# HC32F4A0PGTB register map
File version: 1.0
CPU: CM4 r0p1, little endian, MPU, FPU, 4 interrupt priority bits
Registers are 32-bit, read-write, reset 0x0 unless marked. A register's access mark holds for its fields unless they carry their own. Offsets are from the block's base; [hi:lo] are bit positions; {n}, {i} and the like mark numbered series.

## CAN1 — desc CAN
Base 0x40009000
Same registers: CAN2 0x40078000
0x00 RBUF ro
0x50 TBUF
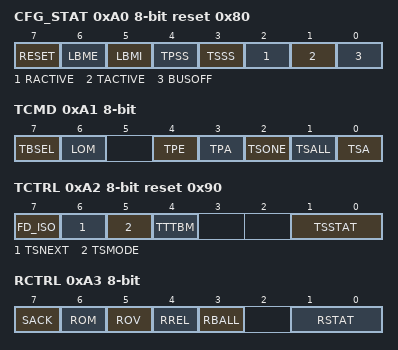
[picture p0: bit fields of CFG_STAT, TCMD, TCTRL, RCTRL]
0xA0 CFG_STAT 8-bit reset 0x80
  [7] RESET, [6] LBME, [5] LBMI, [4] TPSS, [3] TSSS, [2] RACTIVE ro, [1] TACTIVE ro, [0] BUSOFF
0xA1 TCMD 8-bit
  [7] TBSEL, [6] LOM, [4] TPE, [3] TPA, [2] TSONE, [1] TSALL, [0] TSA
0xA2 TCTRL 8-bit reset 0x90
  [7] FD_ISO, [6] TSNEXT, [5] TSMODE, [4] TTTBM, [1:0] TSSTAT ro
0xA3 RCTRL 8-bit
  [7] SACK, [6] ROM, [5] ROV ro, [4] RREL, [3] RBALL, [1:0] RSTAT ro
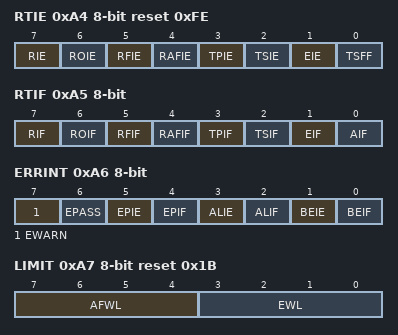
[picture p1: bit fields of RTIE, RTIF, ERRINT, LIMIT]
0xA4 RTIE 8-bit reset 0xFE
  [7] RIE, [6] ROIE, [5] RFIE, [4] RAFIE, [3] TPIE, [2] TSIE, [1] EIE, [0] TSFF ro
0xA5 RTIF 8-bit
  [7] RIF, [6] ROIF, [5] RFIF, [4] RAFIF, [3] TPIF, [2] TSIF, [1] EIF, [0] AIF
0xA6 ERRINT 8-bit
  [7] EWARN ro, [6] EPASS ro, [5] EPIE, [4] EPIF, [3] ALIE, [2] ALIF, [1] BEIE, [0] BEIF
0xA7 LIMIT 8-bit reset 0x1B
  [7:4] AFWL, [3:0] EWL
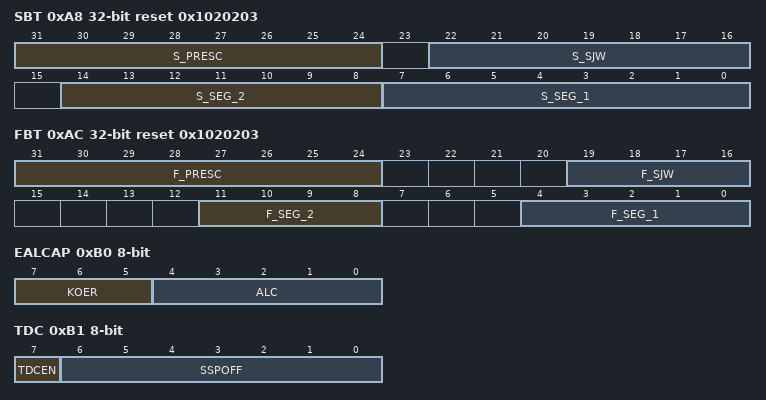
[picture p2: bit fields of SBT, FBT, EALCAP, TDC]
0xA8 SBT reset 0x1020203
  [31:24] S_PRESC, [22:16] S_SJW, [14:8] S_SEG_2, [7:0] S_SEG_1
0xAC FBT reset 0x1020203
  [31:24] F_PRESC, [19:16] F_SJW, [11:8] F_SEG_2, [4:0] F_SEG_1
0xB0 EALCAP 8-bit ro
  [7:5] KOER, [4:0] ALC
0xB1 TDC 8-bit
  [7] TDCEN, [6:0] SSPOFF
0xB2 RECNT 8-bit
0xB3 TECNT 8-bit
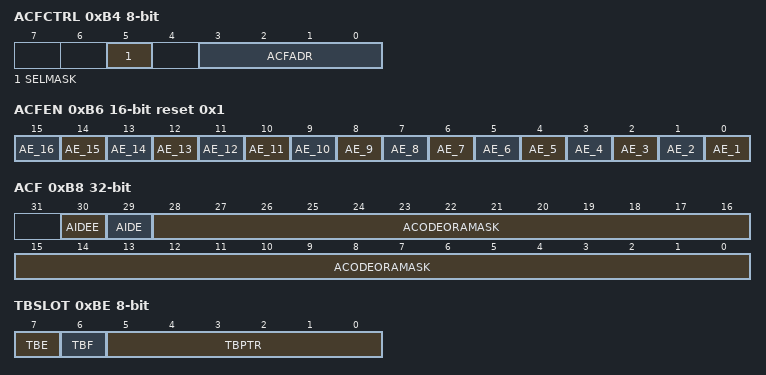
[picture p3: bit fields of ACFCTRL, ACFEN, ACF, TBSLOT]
0xB4 ACFCTRL 8-bit
  [5] SELMASK, [3:0] ACFADR
0xB6 ACFEN 16-bit reset 0x1
  [n-1] AE_{n} (n=1..16)
0xB8 ACF
  [30] AIDEE, [29] AIDE, [28:0] ACODEORAMASK
0xBE TBSLOT 8-bit
  [7] TBE, [6] TBF, [5:0] TBPTR
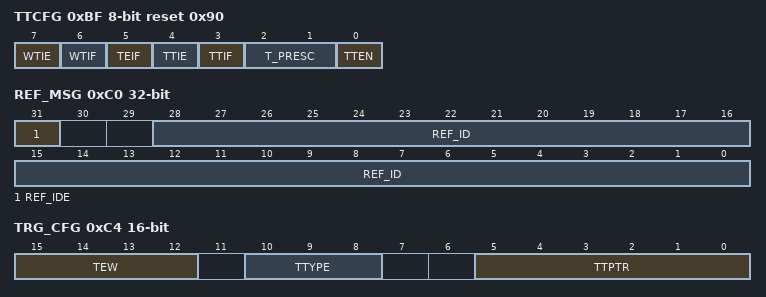
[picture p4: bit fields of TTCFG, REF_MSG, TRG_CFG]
0xBF TTCFG 8-bit reset 0x90
  [7] WTIE, [6] WTIF, [5] TEIF, [4] TTIE, [3] TTIF, [2:1] T_PRESC, [0] TTEN
0xC0 REF_MSG
  [31] REF_IDE, [28:0] REF_ID
0xC4 TRG_CFG 16-bit
  [15:12] TEW, [10:8] TTYPE, [5:0] TTPTR
0xC6 TT_TRIG 16-bit
0xC8 TT_WTRIG 16-bit reset 0xFFFF

## CMP1 — desc CMP
Base 0x4004A000
Same registers: CMP3 0x4004A400
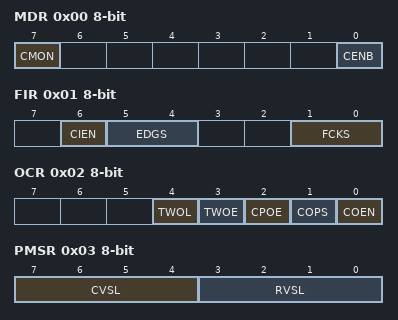
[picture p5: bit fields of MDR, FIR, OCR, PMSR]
0x00 MDR 8-bit
  [7] CMON ro, [0] CENB
0x01 FIR 8-bit
  [6] CIEN, [5:4] EDGS, [1:0] FCKS
0x02 OCR 8-bit
  [4] TWOL, [3] TWOE, [2] CPOE, [1] COPS, [0] COEN
0x03 PMSR 8-bit
  [7:4] CVSL, [3:0] RVSL
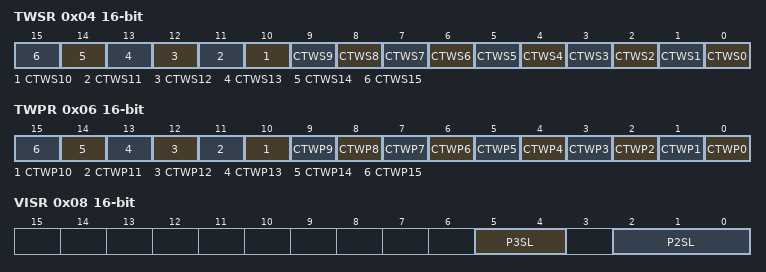
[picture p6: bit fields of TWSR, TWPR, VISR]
0x04 TWSR 16-bit
  [n] CTWS{n} (n=0..15)
0x06 TWPR 16-bit
  [n] CTWP{n} (n=0..15)
0x08 VISR 16-bit
  [5:4] P3SL, [2:0] P2SL

## CMP2 — desc CMP
Base 0x4004A010
Same registers: CMP4 0x4004A410
Registers as CMP1; these are added or differ:
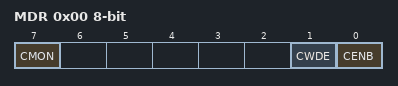
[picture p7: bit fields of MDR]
0x00 MDR 8-bit
  [7] CMON ro, [1] CWDE, [0] CENB

## CMU
Base 0x4004C400
0x00 XTAL32CR 8-bit
  [0] XTAL32STP
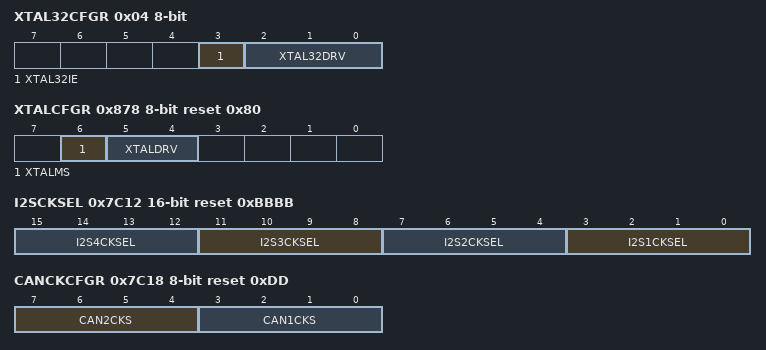
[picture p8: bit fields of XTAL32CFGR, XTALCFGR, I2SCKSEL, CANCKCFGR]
0x04 XTAL32CFGR 8-bit (reset mask 0x7)
  [3] XTAL32IE, [2:0] XTAL32DRV
0x14 XTAL32NFR 8-bit
  [1:0] XTAL32NF
0x1C LRCCR 8-bit
  [0] LRCSTP
0x24 LRCTRM 8-bit
0x2C RTCLRCTRM 8-bit
0x878 XTALCFGR 8-bit reset 0x80
  [6] XTALMS, [5:4] XTALDRV
0x7C10 PERICKSEL 16-bit
  [3:0] PERICKSEL
0x7C12 I2SCKSEL 16-bit reset 0xBBBB
  [4n-1:4n-4] I2S{n}CKSEL (n=1..4)
0x7C18 CANCKCFGR 8-bit reset 0xDD
  [7:4] CAN2CKS, [3:0] CAN1CKS
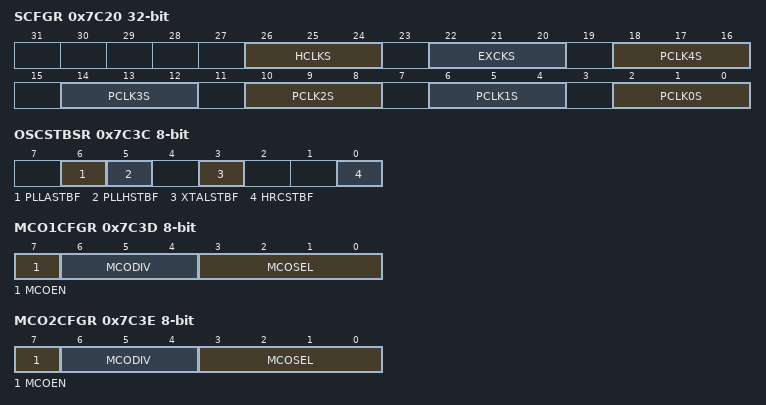
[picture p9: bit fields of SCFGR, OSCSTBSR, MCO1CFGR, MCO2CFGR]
0x7C20 SCFGR
  [26:24] HCLKS, [22:20] EXCKS, [4n+2:4n] PCLK{n}S (n=0..4)
0x7C24 USBCKCFGR 8-bit reset 0x40
  [7:4] USBCKS
0x7C26 CKSWR 8-bit reset 0x1
  [2:0] CKSW
0x7C2A PLLHCR 8-bit reset 0x1
  [0] PLLHOFF
0x7C2E PLLACR 8-bit reset 0x1
  [0] PLLAOFF
0x7C32 XTALCR 8-bit reset 0x1
  [0] XTALSTP
0x7C36 HRCCR 8-bit reset 0x1
  [0] HRCSTP
0x7C38 MRCCR 8-bit reset 0x80
  [0] MRCSTP
0x7C3C OSCSTBSR 8-bit
  [6] PLLASTBF, [5] PLLHSTBF, [3] XTALSTBF, [0] HRCSTBF
0x7C3D MCO1CFGR 8-bit
  [7] MCOEN, [6:4] MCODIV, [3:0] MCOSEL
0x7C3E MCO2CFGR 8-bit
  [7] MCOEN, [6:4] MCODIV, [3:0] MCOSEL
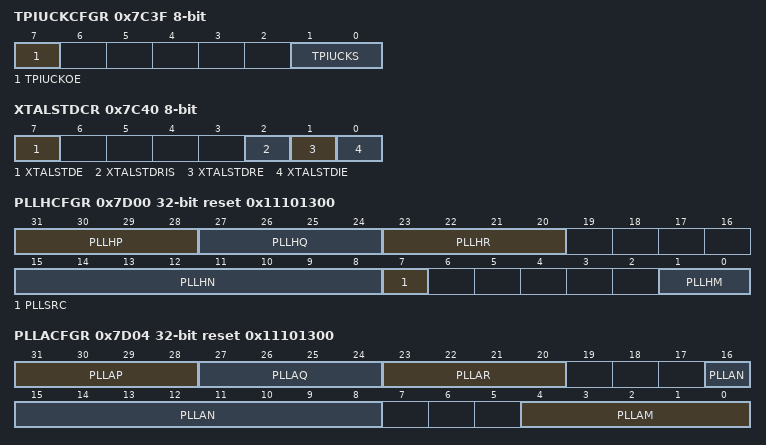
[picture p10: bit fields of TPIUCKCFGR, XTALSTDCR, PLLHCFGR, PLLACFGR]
0x7C3F TPIUCKCFGR 8-bit
  [7] TPIUCKOE, [1:0] TPIUCKS
0x7C40 XTALSTDCR 8-bit
  [7] XTALSTDE, [2] XTALSTDRIS, [1] XTALSTDRE, [0] XTALSTDIE
0x7C41 XTALSTDSR 8-bit
  [0] XTALSTDF
0x7C61 MRCTRM 8-bit
0x7C62 HRCTRM 8-bit
0x7CA2 XTALSTBCR 8-bit reset 0x5
  [3:0] XTALSTB
0x7D00 PLLHCFGR reset 0x11101300
  [31:28] PLLHP, [27:24] PLLHQ, [23:20] PLLHR, [15:8] PLLHN, [7] PLLSRC, [1:0] PLLHM
0x7D04 PLLACFGR reset 0x11101300
  [31:28] PLLAP, [27:24] PLLAQ, [23:20] PLLAR, [16:8] PLLAN, [4:0] PLLAM
